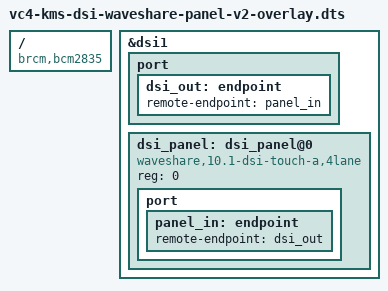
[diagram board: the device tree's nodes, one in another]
/*
 * vc4-kms-dsi-ili9881-5inch-overlay.dts
 */

/dts-v1/;
/plugin/;

/ {
	compatible = "brcm,bcm2835";


	dsi_frag: fragment@0 {
		target = <&dsi1>;
		__overlay__  {
			#address-cells = <1>;
			#size-cells = <0>;
			status = "okay";

			port {
				dsi_out: endpoint {
					remote-endpoint = <&panel_in>;
				};
			};

			dsi_panel: dsi_panel@0 {
				reg = <0>;
				compatible = "waveshare,10.1-dsi-touch-a,4lane";
   			// panel-orientation = "left_side_up";

				port {
					panel_in: endpoint {
						remote-endpoint = <&dsi_out>;
					};
				};
			};
		};
	};

	__overrides__ {
		4_0_inch_a = <&dsi_panel>, "compatible=waveshare,4.0-dsi-touch-a";
		5_0_inch_a = <&dsi_panel>, "compatible=waveshare,5.0-dsi-touch-a";
		5_5_inch_a = <&dsi_panel>, "compatible=waveshare,5.5-dsi-touch-a";
		7_0_inch_a = <&dsi_panel>, "compatible=waveshare,7.0-dsi-touch-a";
		7_0_inch_b = <&dsi_panel>, "compatible=waveshare,7.0-dsi-touch-b";
		7_0_inch_c = <&dsi_panel>, "compatible=waveshare,7.0-dsi-touch-c";
		8_0_inch_a = <&dsi_panel>, "compatible=waveshare,8.0-dsi-touch-a";
		8_0_inch_a_4lane = <&dsi_panel>, "compatible=waveshare,8.0-dsi-touch-a,4lane";
		8_1_inch_a = <&dsi_panel>, "compatible=waveshare,8.1-dsi-touch-a";
		10_1_inch_a = <&dsi_panel>, "compatible=waveshare,10.1-dsi-touch-a";
		10_1_inch_a_4lane = <&dsi_panel>, "compatible=waveshare,10.1-dsi-touch-a,4lane";
		10_1_inch_b = <&dsi_panel>, "compatible=waveshare,10.1-dsi-touch-b";
		10_1_inch_b_4lane = <&dsi_panel>, "compatible=waveshare,10.1-dsi-touch-b,4lane";
	};
};
